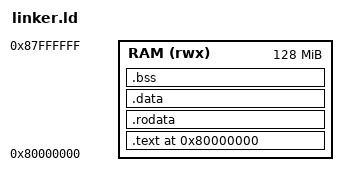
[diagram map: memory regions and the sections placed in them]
OUTPUT_ARCH(riscv)
ENTRY(_start)

MEMORY
{
  RAM (rwx) : ORIGIN = 0x80000000, LENGTH = 128M
}

SECTIONS
{
  . = 0x80000000;
  
  .text : {
    *(.text.init)
    *(.text .text.*)
  } > RAM

  .rodata : {
    *(.rodata .rodata.*)
  } > RAM

  .data : {
    *(.data .data.*)
  } > RAM

  .bss : {
    *(.bss .bss.*)
    *(COMMON)
  } > RAM

  _end = .;
}
